# apollo4p register map
Vendor: Ambiq Micro; Series: Apollo; File version: 1.0
CPU: CM4 r1p0, little endian, MPU, FPU, I-cache, D-cache, VTOR, ITCM, DTCM, 3 interrupt priority bits, 0 interrupts
Registers are 32-bit, read-write, reset 0x0 unless marked. A register's access mark holds for its fields unless they carry their own. Offsets are from the block's base; [hi:lo] are bit positions; 'fields as' and 'values as' point back to an identical list.

## WDT — Watchdog Timer
Base 0x40024000
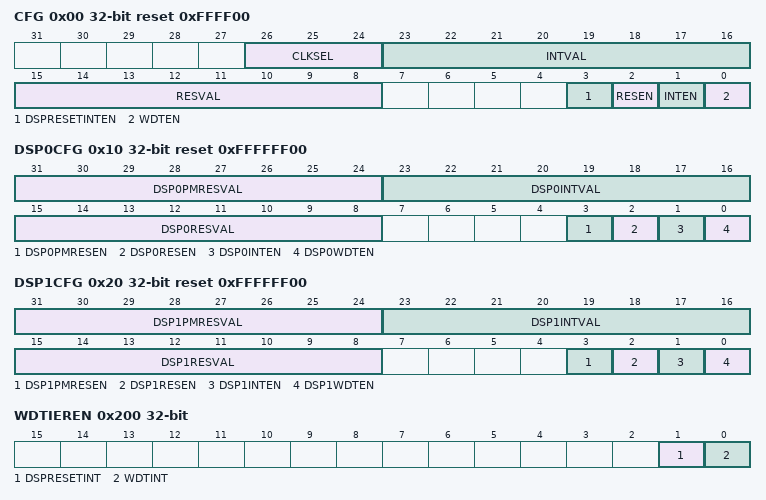
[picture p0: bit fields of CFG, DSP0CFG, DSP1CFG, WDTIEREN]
0x00 CFG reset 0xFFFF00 — This is the configuration register for the watch dog timer. It controls the enable, interrupt set, clocks for the timer, the compare values for the counters to trigger a reset or interrupt. This register can only be written to if the watch dog timer is unlocked (WDTLOCK is not set).
  [26:24] CLKSEL — Select the frequency for the WDT. All values not enumerated below are undefined.
    0=OFF (Low Power Mode. This setting disables the watch dog timer.); 1=128HZ (128 Hz LFRC clock.); 2=16HZ (16 Hz LFRC clock.); 3=1HZ (1 Hz LFRC clock.); 4=1_16HZ (1/16th Hz LFRC clock.)
  [23:16] INTVAL — This bitfield is the compare value for counter bits 7:0 to generate a watchdog interrupt.
  [15:8] RESVAL — This bitfield is the compare value for counter bits 7:0 to generate a watchdog reset. This will cause a software reset.
  [3] DSPRESETINTEN — This bitfield enables the DSP Reset Interrupt. This interrupt is provided to the ARM CPU to notify it that a DSP's WDT has expired and a reset has been issued to one of the DSP cores.
  [2] RESEN — This bitfield enables the WDT reset. This needs to be set together with the WDREN bit in REG_RSTGEN_CFG register (in reset gen) to trigger the reset.
  [1] INTEN — This bitfield enables the WDT interrupt. Note : This bit must be set before the interrupt status bit will reflect a watchdog timer expiration. The IER interrupt register must also be enabled for a WDT interrupt to be sent to the NVIC.
  [0] WDTEN — This bitfield enables the WDT.
0x04 RSTRT — This register will Restart the watchdog timer. Writing a special key value into this register will result in the watch dog timer being reset, so that the count will start again. It is expected that the software will periodically write to this register to indicate that the system is functional. The watch dog timer can continue running when the system is in deep sleep, and the interrupt will trigger the wake. After the wake, the core can reset the watch dog timer.
  [7:0] RSTRT — Writing 0xB2 to WDTRSTRT restarts the watchdog timer. This is a write only register. Reading this register will only provide all 0.
    178=KEYVALUE (This is the key value to write to WDTRSTRT to restart the WDT. This is a write only register.); 0=DEFAULT (Default/Reset value. This is a write only register.)
0x08 LOCK — This register locks the watch dog timer. Once it is locked, the configuration register (WDTCFG) for watch dog timer cannot be written to.
  [7:0] LOCK — Writing 0x3A locks the watchdog timer. Once locked, the WDTCFG reg cannot be written and WDTEN is set.
    58=KEYVALUE (This is the key value to write to WDTLOCK to lock the WDT.); 0=DEFAULT (Default/Reset value.)
0x0C COUNT — This register holds the current count for the watch dog timer. This is a read only register. SW cannot set the value in the counter, but can reset it.
  [7:0] COUNT — Read-Only current value of the WDT counter
0x10 DSP0CFG reset 0xFFFFFF00 — This is the configuration register for the DSP0 watch dog timer. It controls the enable, interrupt set, clocks for the timer, the compare values for the counters to trigger a reset or interrupt. This register can only be written to if the associated DSP0TLOCK is not set.
  [31:24] DSP0PMRESVAL — This bitfield is the compare value for counter bits 7:0 to generate a watchdog reset. This will cause a software reset to the DSP Power Management logic if the PMRESEN bit is set and optionally interrupt the CPU.
  [23:16] DSP0INTVAL — This bitfield is the compare value for counter bits 7:0 to generate a watchdog interrupt.
  [15:8] DSP0RESVAL — This bitfield is the compare value for counter bits 7:0 to generate a watchdog reset for the DSP logic. This will cause a software reset to the DSP core if the RESEN bit is set and optionally interrupt the CPU.
  [3] DSP0PMRESEN — This bitfield enables the DSP0 Power Controller (PM) reset. This needs to be set together with the DSP0WDTEN bit to allow the reset to trigger.
  [2] DSP0RESEN — This bitfield enables the DSP0 reset.
  [1] DSP0INTEN — This bitfield enables the DSP0 WDT interrupt. Note : This bit must be set before the interrupt status bit will reflect a watchdog timer expiration. The IER interrupt register must also be enabled for a WDT interrupt to be sent to the NVIC.
  [0] DSP0WDTEN — This bitfield enables the WDT. Setting the lock implicitly sets the WTDEN bit as well.
0x14 DSP0RSTRT — This register will restart the watchdog timer. Writing a special key value into this register will result in the watch dog timer being reset, so that the count will start again. It is expected that the software will periodically write to this register to indicate that the system is functional. The watch dog timer can continue running when the system is in deep sleep, and the interrupt will trigger the wake. After the wake, the core can reset the watch dog timer.
  [7:0] DSP0RSTART — Writing 0x69 to DSP0RSTRT restarts the watchdog timer. This is a write only register. Reading this register will return 0.
    105=KEYVALUE (This is the key value to write to WDTRSTRT to restart the WDT. This is a write only register.); 0=DEFAULT (Reset value)
0x18 DSP0TLOCK — This register locks the watch dog timer. Once it is locked, the configuration register (DSP0CFG) for watch dog timer cannot be written to and the timer is automatically enabled (WDTEN is set).
  [7:0] DSP0LOCK — Writing 0xa7 locks the watchdog timer. Once locked, the WDTCFG reg cannot be written and WDTEN is set.
    167=KEYVALUE (This is the key value to write to WDTLOCK to lock the WDT.); 0=DEFAULT (Reset Value.)
0x1C DSP0COUNT — This register holds the current count for the watch dog timer. This is a read only register. SW cannot set the value in the counter, but can reset it.
  [7:0] DSP0COUNT — Read-Only current value of the WDT counter
0x20 DSP1CFG reset 0xFFFFFF00 — This is the configuration register for the DSP1 watch dog timer. It controls the enable, interrupt set, clocks for the timer, the compare values for the counters to trigger a reset or interrupt. This register can only be written to if the associated DSP1TLOCK is not set.
  [31:24] DSP1PMRESVAL — This bitfield is the compare value for counter bits 7:0 to generate a watchdog reset. This will cause a software reset to the DSP Power Management logic if the PMRESEN bit is set and optionally interrupt the CPU.
  [23:16] DSP1INTVAL — This bitfield is the compare value for counter bits 7:0 to generate a watchdog interrupt.
  [15:8] DSP1RESVAL — This bitfield is the compare value for counter bits 7:0 to generate a watchdog reset for the DSP logic. This will cause a software reset to the DSP core if the RESEN bit is set and optionally interrupt the CPU.
  [3] DSP1PMRESEN — This bitfield enables the DSP1 Power Controller (PM) reset. This needs to be set together with the DSP1WDTEN bit to allow the reset to trigger.
  [2] DSP1RESEN — This bitfield enables the DSP1 reset.
  [1] DSP1INTEN — This bitfield enables the DSP1 WDT interrupt. Note : This bit must be set before the interrupt status bit will reflect a watchdog timer expiration. The IER interrupt register must also be enabled for a WDT interrupt to be sent to the NVIC.
  [0] DSP1WDTEN — This bitfield enables the WDT. Setting the lock implicitly sets the WTDEN bit as well.
0x24 DSP1RSTRT — This register will restart the watchdog timer. Writing a special key value into this register will result in the watch dog timer being reset, so that the count will start again. It is expected that the software will periodically write to this register to indicate that the system is functional. The watch dog timer can continue running when the system is in deep sleep, and the interrupt will trigger the wake. After the wake, the core can reset the watch dog timer.
  [7:0] DSP1RSTART — Writing 0xd2 to DSP1RSTRT restarts the watchdog timer. This is a write only register. Reading this register will return 0.
    210=KEYVALUE (This is the key value to write to WDTRSTRT to restart the WDT. This is a write only register.); 0=DEFAULT (Reset value)
0x28 DSP1TLOCK — This register locks the watch dog timer. Once it is locked, the configuration register (DSP1CFG) for watch dog timer cannot be written to and the timer is automatically enabled (WDTEN is set).
  [7:0] DSP1LOCK — Writing 0x4e locks the watchdog timer. Once locked, the WDTCFG reg cannot be written and WDTEN is set.
    78=KEYVALUE (This is the key value to write to WDTLOCK to lock the WDT.); 0=DEFAULT (Reset Value.)
0x2C DSP1COUNT — This register holds the current count for the watch dog timer. This is a read only register. SW cannot set the value in the counter, but can reset it.
  [7:0] DSP1COUNT — Read-Only current value of the WDT counter
0x200 WDTIEREN — Set bits in this register to allow this module to generate the corresponding interrupt.
  [1] DSPRESETINT — Indicates that one of the DSP timers has issued a reset or pmreset to the DSP core. This is used to interrupt the main CPU.
  [0] WDTINT — Watchdog Timer Interrupt.
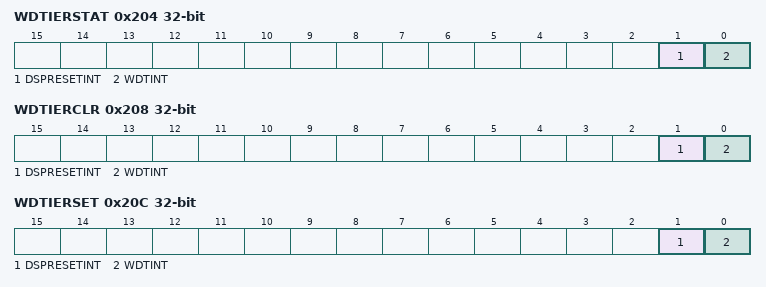
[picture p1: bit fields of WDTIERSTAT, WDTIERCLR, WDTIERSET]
0x204 WDTIERSTAT — Read bits from this register to discover the cause of a recent interrupt.
  fields as WDTIEREN
0x208 WDTIERCLR — Write a 1 to a bit in this register to clear the interrupt status associated with that bit.
  fields as WDTIEREN
0x20C WDTIERSET — Write a 1 to a bit in this register to instantly generate an interrupt from this module. (Generally used for testing purposes).
  fields as WDTIEREN
0x210 DSP0IEREN — Set bits in this register to allow this module to generate the corresponding interrupt.
  [0] DSP0INT — DSP0 Watchdog Timer Interrupt.
0x214 DSP0IERSTAT — Read bits from this register to discover the cause of a recent interrupt.
  [0] DSP0INT — DSP0 Watchdog Timer Interrupt.
0x218 DSP0IERCLR — Write a 1 to a bit in this register to clear the interrupt status associated with that bit.
  [0] DSP0INT — DSP0 Watchdog Timer Interrupt.
0x21C DSP0IERSET — Write a 1 to a bit in this register to instantly generate an interrupt from this module. (Generally used for testing purposes).
  [0] DSP0INT — DSP0 Watchdog Timer Interrupt.
0x220 DSP1IEREN — Set bits in this register to allow this module to generate the corresponding interrupt.
  [0] DSP1INT — DSP0 Watchdog Timer Interrupt.
0x224 DSP1IERSTAT — Read bits from this register to discover the cause of a recent interrupt.
  [0] DSP1INT — DSP0 Watchdog Timer Interrupt.
0x228 DSP1IERCLR — Write a 1 to a bit in this register to clear the interrupt status associated with that bit.
  [0] DSP1INT — DSP0 Watchdog Timer Interrupt.
0x22C DSP1IERSET — Write a 1 to a bit in this register to instantly generate an interrupt from this module. (Generally used for testing purposes).
  [0] DSP1INT — DSP0 Watchdog Timer Interrupt.
